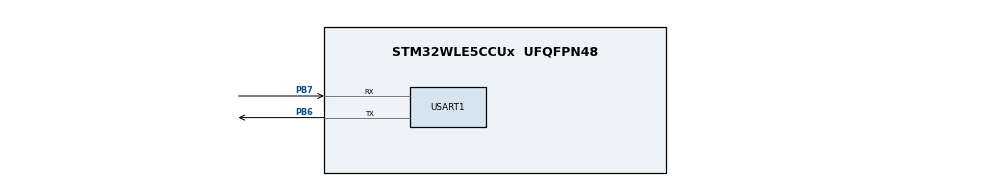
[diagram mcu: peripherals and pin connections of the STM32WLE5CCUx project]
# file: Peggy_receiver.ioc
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Mcu.Family=STM32WL
Mcu.Name=STM32WLE5CCUx
Mcu.Package=UFQFPN48
NVIC.PriorityGroup=NVIC_PRIORITYGROUP_4
PB6.Mode=Asynchronous
PB6.Signal=USART1_TX
PB7.Mode=Asynchronous
PB7.Signal=USART1_RX
ProjectManager.HeapSize=0x200
ProjectManager.StackSize=0x400
ProjectManager.TargetToolchain=STM32CubeIDE
RCC.HSE_VALUE=8000000
RCC.HSI_VALUE=16000000
RCC.LSE_VALUE=32768
RCC.VCOOutputFreq_Value=32000000
USART1.VirtualMode-Asynchronous=VM_ASYNC
VP_SUBGHZ_VS_SUBGHZ.Mode=SUBGHZ_Activate
board=custom

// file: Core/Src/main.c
/* USER CODE BEGIN Header */
/**
  ******************************************************************************
  * @file           : main.c
  * @brief          : Main program body
  ******************************************************************************
  * @attention
  *
  * Copyright (c) 2022 STMicroelectronics.
  * All rights reserved.
  *
  * This software is licensed under terms that can be found in the LICENSE file
  * in the root directory of this software component.
  * If no LICENSE file comes with this software, it is provided AS-IS.
  *
  ******************************************************************************
  */
/* USER CODE END Header */
#include "main.h"

SUBGHZ_HandleTypeDef hsubghz;

UART_HandleTypeDef huart1;

void SystemClock_Config(void);
static void MX_GPIO_Init(void);
static void MX_SUBGHZ_Init(void);
static void MX_USART1_UART_Init(void);

int main(void)
{

  /* MCU Configuration--------------------------------------------------------*/

  /* Reset of all peripherals, Initializes the Flash interface and the Systick. */
  HAL_Init();

  /* Configure the system clock */
  SystemClock_Config();

  /* Initialize all configured peripherals */
  MX_GPIO_Init();
  MX_SUBGHZ_Init();
  MX_USART1_UART_Init();

  /* Infinite loop */
  /* USER CODE BEGIN WHILE */
  while (1)
  {
	  uint8_t data = {0,};
	  SUBGHZSPI_Receive(&hsubghz, &data);
	  /* USER CODE END WHILE */

  }
}

void SystemClock_Config(void)
{
  RCC_OscInitTypeDef RCC_OscInitStruct = {0};
  RCC_ClkInitTypeDef RCC_ClkInitStruct = {0};

  /** Configure the main internal regulator output voltage
  */
  __HAL_PWR_VOLTAGESCALING_CONFIG(PWR_REGULATOR_VOLTAGE_SCALE2);
  /** Initializes the CPU, AHB and APB busses clocks
  */
  RCC_OscInitStruct.OscillatorType = RCC_OSCILLATORTYPE_MSI;
  RCC_OscInitStruct.MSIState = RCC_MSI_ON;
  RCC_OscInitStruct.MSICalibrationValue = RCC_MSICALIBRATION_DEFAULT;
  RCC_OscInitStruct.MSIClockRange = RCC_MSIRANGE_6;
  RCC_OscInitStruct.PLL.PLLState = RCC_PLL_NONE;
  if (HAL_RCC_OscConfig(&RCC_OscInitStruct) != HAL_OK)
  {
    Error_Handler();
  }
  /** Configure the SYSCLKSource, HCLK, PCLK1 and PCLK2 clocks dividers
  */
  RCC_ClkInitStruct.ClockType = RCC_CLOCKTYPE_HCLK3|RCC_CLOCKTYPE_HCLK
                              |RCC_CLOCKTYPE_SYSCLK|RCC_CLOCKTYPE_PCLK1
                              |RCC_CLOCKTYPE_PCLK2;
  RCC_ClkInitStruct.SYSCLKSource = RCC_SYSCLKSOURCE_MSI;
  RCC_ClkInitStruct.AHBCLKDivider = RCC_SYSCLK_DIV1;
  RCC_ClkInitStruct.APB1CLKDivider = RCC_HCLK_DIV1;
  RCC_ClkInitStruct.APB2CLKDivider = RCC_HCLK_DIV1;
  RCC_ClkInitStruct.AHBCLK3Divider = RCC_SYSCLK_DIV1;

  if (HAL_RCC_ClockConfig(&RCC_ClkInitStruct, FLASH_LATENCY_0) != HAL_OK)
  {
    Error_Handler();
  }
}

static void MX_SUBGHZ_Init(void)
{

  hsubghz.Init.BaudratePrescaler = SUBGHZSPI_BAUDRATEPRESCALER_8;
  if (HAL_SUBGHZ_Init(&hsubghz) != HAL_OK)
  {
    Error_Handler();
  }

}

static void MX_USART1_UART_Init(void)
{

  huart1.Instance = USART1;
  huart1.Init.BaudRate = 115200;
  huart1.Init.WordLength = UART_WORDLENGTH_8B;
  huart1.Init.StopBits = UART_STOPBITS_1;
  huart1.Init.Parity = UART_PARITY_NONE;
  huart1.Init.Mode = UART_MODE_TX_RX;
  huart1.Init.HwFlowCtl = UART_HWCONTROL_NONE;
  huart1.Init.OverSampling = UART_OVERSAMPLING_16;
  huart1.Init.OneBitSampling = UART_ONE_BIT_SAMPLE_DISABLE;
  huart1.Init.ClockPrescaler = UART_PRESCALER_DIV1;
  huart1.AdvancedInit.AdvFeatureInit = UART_ADVFEATURE_NO_INIT;
  if (HAL_UART_Init(&huart1) != HAL_OK)
  {
    Error_Handler();
  }
  if (HAL_UARTEx_SetTxFifoThreshold(&huart1, UART_TXFIFO_THRESHOLD_1_8) != HAL_OK)
  {
    Error_Handler();
  }
  if (HAL_UARTEx_SetRxFifoThreshold(&huart1, UART_RXFIFO_THRESHOLD_1_8) != HAL_OK)
  {
    Error_Handler();
  }
  if (HAL_UARTEx_DisableFifoMode(&huart1) != HAL_OK)
  {
    Error_Handler();
  }

}

static void MX_GPIO_Init(void)
{

  /* GPIO Ports Clock Enable */
  __HAL_RCC_GPIOB_CLK_ENABLE();

}

void Error_Handler(void)
{
  __disable_irq();
  while (1)
  {
  }
}
